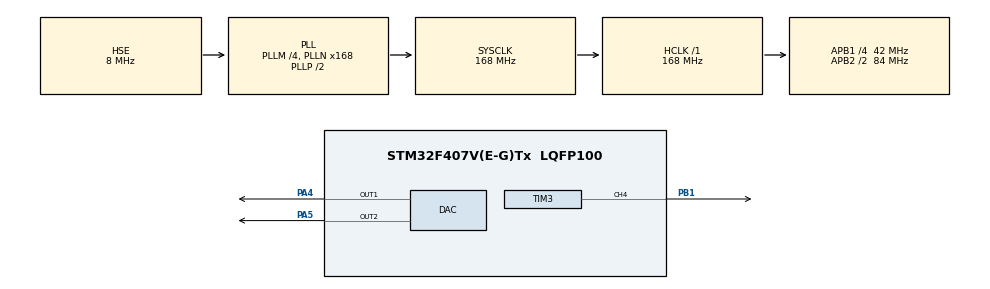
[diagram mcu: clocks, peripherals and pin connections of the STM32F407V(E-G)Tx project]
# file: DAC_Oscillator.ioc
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DAC.DAC_Trigger=DAC_TRIGGER_T2_TRGO
DAC.DAC_Trigger2=DAC_TRIGGER_T2_TRGO
Dma.DAC1.0.Direction=DMA_MEMORY_TO_PERIPH
Dma.DAC1.0.FIFOMode=DMA_FIFOMODE_DISABLE
Dma.DAC1.0.Instance=DMA1_Stream5
Dma.DAC1.0.MemDataAlignment=DMA_MDATAALIGN_HALFWORD
Dma.DAC1.0.MemInc=DMA_MINC_ENABLE
Dma.DAC1.0.Mode=DMA_CIRCULAR
Dma.DAC1.0.PeriphDataAlignment=DMA_PDATAALIGN_HALFWORD
Dma.DAC1.0.PeriphInc=DMA_PINC_DISABLE
Dma.DAC1.0.Priority=DMA_PRIORITY_VERY_HIGH
Dma.DAC2.1.Direction=DMA_MEMORY_TO_PERIPH
Dma.DAC2.1.FIFOMode=DMA_FIFOMODE_DISABLE
Dma.DAC2.1.Instance=DMA1_Stream6
Dma.DAC2.1.MemDataAlignment=DMA_MDATAALIGN_HALFWORD
Dma.DAC2.1.MemInc=DMA_MINC_ENABLE
Dma.DAC2.1.Mode=DMA_CIRCULAR
Dma.DAC2.1.PeriphDataAlignment=DMA_PDATAALIGN_HALFWORD
Dma.DAC2.1.PeriphInc=DMA_PINC_DISABLE
Dma.DAC2.1.Priority=DMA_PRIORITY_HIGH
Dma.Request0=DAC1
Dma.Request1=DAC2
Mcu.Family=STM32F4
Mcu.Name=STM32F407V(E-G)Tx
Mcu.Package=LQFP100
NVIC.DMA1_Stream5_IRQn=true\:0\:0\:false\:false\:true\:false\:true\:true
NVIC.DMA1_Stream6_IRQn=true\:0\:0\:false\:false\:true\:false\:true\:true
NVIC.PriorityGroup=NVIC_PRIORITYGROUP_4
PA13.Mode=Serial_Wire
PA13.Signal=SYS_JTMS-SWDIO
PA14.Mode=Serial_Wire
PA14.Signal=SYS_JTCK-SWCLK
PA4.Signal=COMP_DAC1_group
PA5.Signal=COMP_DAC2_group
PB1.Signal=S_TIM3_CH4
PH0-OSC_IN.Mode=HSE-External-Oscillator
PH0-OSC_IN.Signal=RCC_OSC_IN
PH1-OSC_OUT.Mode=HSE-External-Oscillator
PH1-OSC_OUT.Signal=RCC_OSC_OUT
ProjectManager.HeapSize=0x200
ProjectManager.StackSize=0x400
ProjectManager.TargetToolchain=STM32CubeIDE
RCC.48MHZClocksFreq_Value=84000000
RCC.AHBFreq_Value=168000000
RCC.APB1CLKDivider=RCC_HCLK_DIV4
RCC.APB1Freq_Value=42000000
RCC.APB1TimFreq_Value=84000000
RCC.APB2CLKDivider=RCC_HCLK_DIV2
RCC.APB2Freq_Value=84000000
RCC.APB2TimFreq_Value=168000000
RCC.CortexFreq_Value=168000000
RCC.HCLKFreq_Value=168000000
RCC.HSE_VALUE=8000000
RCC.HSI_VALUE=16000000
RCC.LSE_VALUE=32768
RCC.PLLM=4
RCC.PLLN=168
RCC.PLLSourceVirtual=RCC_PLLSOURCE_HSE
RCC.SYSCLKFreq_VALUE=168000000
RCC.SYSCLKSource=RCC_SYSCLKSOURCE_PLLCLK
RCC.VCOOutputFreq_Value=336000000
SH.COMP_DAC1_group.0=DAC_OUT1,DAC_OUT1
SH.COMP_DAC2_group.0=DAC_OUT2,DAC_OUT2
SH.S_TIM3_CH4.0=TIM3_CH4,PWM Generation4 CH4
TIM2.Period=5-1
TIM2.Prescaler=84-1
TIM2.TIM_MasterOutputTrigger=TIM_TRGO_UPDATE
TIM3.Channel-PWM\ Generation4\ CH4=TIM_CHANNEL_4
TIM3.Period=1000-1
TIM3.Prescaler=84-1
TIM3.Pulse-PWM\ Generation4\ CH4=500
VP_TIM2_VS_ClockSourceINT.Mode=Internal
board=custom

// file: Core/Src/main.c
/* USER CODE BEGIN Header */
/**
  ******************************************************************************
  * @file           : main.c
  * @brief          : Main program body
  ******************************************************************************
  * @attention
  *
  * Copyright (c) 2025 STMicroelectronics.
  * All rights reserved.
  *
  * This software is licensed under terms that can be found in the LICENSE file
  * in the root directory of this software component.
  * If no LICENSE file comes with this software, it is provided AS-IS.
  *
  ******************************************************************************
  */
/* USER CODE END Header */
#include "main.h"

/* USER CODE BEGIN Includes */
#include "math.h"
/* USER CODE END Includes */

/* USER CODE BEGIN PD */
#define SAMPLE 200
#define PI 3.1415926
/* USER CODE END PD */

DAC_HandleTypeDef hdac;
DMA_HandleTypeDef hdma_dac1;
DMA_HandleTypeDef hdma_dac2;

TIM_HandleTypeDef htim2;
TIM_HandleTypeDef htim3;

void SystemClock_Config(void);
static void MX_GPIO_Init(void);
static void MX_DMA_Init(void);
static void MX_DAC_Init(void);
static void MX_TIM2_Init(void);
static void MX_TIM3_Init(void);

/* USER CODE BEGIN 0 */
uint16_t sinwave[SAMPLE] = {0};
uint16_t triwave[SAMPLE] = {0};

void calcsin()
{
	for (int i=0; i < SAMPLE; i++)
	{
		sinwave[i] = ((sin((i*2*PI)/SAMPLE) + 1)*(4096/2));
	}
}

void calctriangle()
{
    for (int i = 0; i < SAMPLE; i++)
    {
        if (i < SAMPLE/2)
        {
            // İlk yarı: 0 → maksimum
            triwave[i] = (uint16_t)(i * (4095.0 / (SAMPLE/2)));
        }
        else
        {
            // İkinci yarı: maksimum → 0
            triwave[i] = (uint16_t)((SAMPLE - i) * (4095.0 / (SAMPLE/2)));
        }
    }
}
/* USER CODE END 0 */

int main(void)
{

  /* MCU Configuration--------------------------------------------------------*/

  /* Reset of all peripherals, Initializes the Flash interface and the Systick. */
  HAL_Init();

  /* Configure the system clock */
  SystemClock_Config();

  /* Initialize all configured peripherals */
  MX_GPIO_Init();
  MX_DMA_Init();
  MX_DAC_Init();
  MX_TIM2_Init();
  MX_TIM3_Init();
  /* USER CODE BEGIN 2 */
  HAL_TIM_Base_Start(&htim2);
  HAL_TIM_PWM_Start_IT(&htim3, TIM_CHANNEL_4);
  calcsin();
  calctriangle();
  HAL_DAC_Start_DMA(&hdac, DAC_CHANNEL_1, sinwave, SAMPLE, DAC_ALIGN_12B_R);
  HAL_DAC_Start_DMA(&hdac, DAC_CHANNEL_2, triwave, SAMPLE, DAC_ALIGN_12B_R);
  /* USER CODE END 2 */

  /* Infinite loop */
  while (1)
  {

  }
}

void SystemClock_Config(void)
{
  RCC_OscInitTypeDef RCC_OscInitStruct = {0};
  RCC_ClkInitTypeDef RCC_ClkInitStruct = {0};

  /** Configure the main internal regulator output voltage
  */
  __HAL_RCC_PWR_CLK_ENABLE();
  __HAL_PWR_VOLTAGESCALING_CONFIG(PWR_REGULATOR_VOLTAGE_SCALE1);

  /** Initializes the RCC Oscillators according to the specified parameters
  * in the RCC_OscInitTypeDef structure.
  */
  RCC_OscInitStruct.OscillatorType = RCC_OSCILLATORTYPE_HSE;
  RCC_OscInitStruct.HSEState = RCC_HSE_ON;
  RCC_OscInitStruct.PLL.PLLState = RCC_PLL_ON;
  RCC_OscInitStruct.PLL.PLLSource = RCC_PLLSOURCE_HSE;
  RCC_OscInitStruct.PLL.PLLM = 4;
  RCC_OscInitStruct.PLL.PLLN = 168;
  RCC_OscInitStruct.PLL.PLLP = RCC_PLLP_DIV2;
  RCC_OscInitStruct.PLL.PLLQ = 4;
  if (HAL_RCC_OscConfig(&RCC_OscInitStruct) != HAL_OK)
  {
    Error_Handler();
  }

  /** Initializes the CPU, AHB and APB buses clocks
  */
  RCC_ClkInitStruct.ClockType = RCC_CLOCKTYPE_HCLK|RCC_CLOCKTYPE_SYSCLK
                              |RCC_CLOCKTYPE_PCLK1|RCC_CLOCKTYPE_PCLK2;
  RCC_ClkInitStruct.SYSCLKSource = RCC_SYSCLKSOURCE_PLLCLK;
  RCC_ClkInitStruct.AHBCLKDivider = RCC_SYSCLK_DIV1;
  RCC_ClkInitStruct.APB1CLKDivider = RCC_HCLK_DIV4;
  RCC_ClkInitStruct.APB2CLKDivider = RCC_HCLK_DIV2;

  if (HAL_RCC_ClockConfig(&RCC_ClkInitStruct, FLASH_LATENCY_5) != HAL_OK)
  {
    Error_Handler();
  }
}

static void MX_DAC_Init(void)
{

  DAC_ChannelConfTypeDef sConfig = {0};

  /** DAC Initialization
  */
  hdac.Instance = DAC;
  if (HAL_DAC_Init(&hdac) != HAL_OK)
  {
    Error_Handler();
  }

  /** DAC channel OUT1 config
  */
  sConfig.DAC_Trigger = DAC_TRIGGER_T2_TRGO;
  sConfig.DAC_OutputBuffer = DAC_OUTPUTBUFFER_ENABLE;
  if (HAL_DAC_ConfigChannel(&hdac, &sConfig, DAC_CHANNEL_1) != HAL_OK)
  {
    Error_Handler();
  }

  /** DAC channel OUT2 config
  */
  if (HAL_DAC_ConfigChannel(&hdac, &sConfig, DAC_CHANNEL_2) != HAL_OK)
  {
    Error_Handler();
  }

}

static void MX_TIM2_Init(void)
{

  TIM_ClockConfigTypeDef sClockSourceConfig = {0};
  TIM_MasterConfigTypeDef sMasterConfig = {0};

  htim2.Instance = TIM2;
  htim2.Init.Prescaler = 84-1;
  htim2.Init.CounterMode = TIM_COUNTERMODE_UP;
  htim2.Init.Period = 5-1;
  htim2.Init.ClockDivision = TIM_CLOCKDIVISION_DIV1;
  htim2.Init.AutoReloadPreload = TIM_AUTORELOAD_PRELOAD_DISABLE;
  if (HAL_TIM_Base_Init(&htim2) != HAL_OK)
  {
    Error_Handler();
  }
  sClockSourceConfig.ClockSource = TIM_CLOCKSOURCE_INTERNAL;
  if (HAL_TIM_ConfigClockSource(&htim2, &sClockSourceConfig) != HAL_OK)
  {
    Error_Handler();
  }
  sMasterConfig.MasterOutputTrigger = TIM_TRGO_UPDATE;
  sMasterConfig.MasterSlaveMode = TIM_MASTERSLAVEMODE_DISABLE;
  if (HAL_TIMEx_MasterConfigSynchronization(&htim2, &sMasterConfig) != HAL_OK)
  {
    Error_Handler();
  }

}

static void MX_TIM3_Init(void)
{

  TIM_MasterConfigTypeDef sMasterConfig = {0};
  TIM_OC_InitTypeDef sConfigOC = {0};

  htim3.Instance = TIM3;
  htim3.Init.Prescaler = 84-1;
  htim3.Init.CounterMode = TIM_COUNTERMODE_UP;
  htim3.Init.Period = 1000-1;
  htim3.Init.ClockDivision = TIM_CLOCKDIVISION_DIV1;
  htim3.Init.AutoReloadPreload = TIM_AUTORELOAD_PRELOAD_DISABLE;
  if (HAL_TIM_PWM_Init(&htim3) != HAL_OK)
  {
    Error_Handler();
  }
  sMasterConfig.MasterOutputTrigger = TIM_TRGO_RESET;
  sMasterConfig.MasterSlaveMode = TIM_MASTERSLAVEMODE_DISABLE;
  if (HAL_TIMEx_MasterConfigSynchronization(&htim3, &sMasterConfig) != HAL_OK)
  {
    Error_Handler();
  }
  sConfigOC.OCMode = TIM_OCMODE_PWM1;
  sConfigOC.Pulse = 500;
  sConfigOC.OCPolarity = TIM_OCPOLARITY_HIGH;
  sConfigOC.OCFastMode = TIM_OCFAST_DISABLE;
  if (HAL_TIM_PWM_ConfigChannel(&htim3, &sConfigOC, TIM_CHANNEL_4) != HAL_OK)
  {
    Error_Handler();
  }
  HAL_TIM_MspPostInit(&htim3);

}

static void MX_DMA_Init(void)
{

  /* DMA controller clock enable */
  __HAL_RCC_DMA1_CLK_ENABLE();

  /* DMA interrupt init */
  /* DMA1_Stream5_IRQn interrupt configuration */
  HAL_NVIC_SetPriority(DMA1_Stream5_IRQn, 0, 0);
  HAL_NVIC_EnableIRQ(DMA1_Stream5_IRQn);
  /* DMA1_Stream6_IRQn interrupt configuration */
  HAL_NVIC_SetPriority(DMA1_Stream6_IRQn, 0, 0);
  HAL_NVIC_EnableIRQ(DMA1_Stream6_IRQn);

}

static void MX_GPIO_Init(void)
{

  /* GPIO Ports Clock Enable */
  __HAL_RCC_GPIOH_CLK_ENABLE();
  __HAL_RCC_GPIOA_CLK_ENABLE();
  __HAL_RCC_GPIOB_CLK_ENABLE();

}

void Error_Handler(void)
{
  __disable_irq();
  while (1)
  {
  }
}
